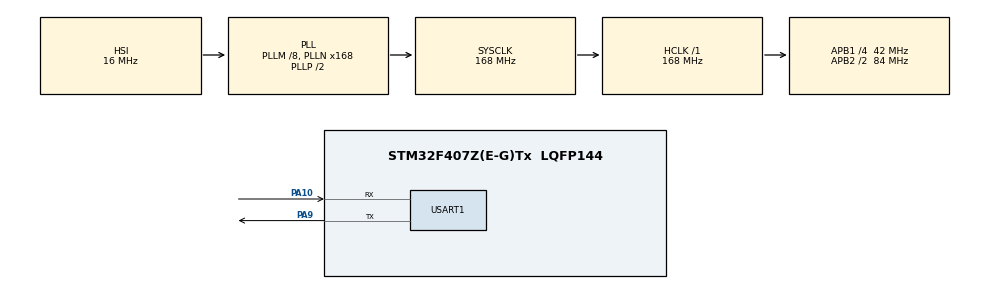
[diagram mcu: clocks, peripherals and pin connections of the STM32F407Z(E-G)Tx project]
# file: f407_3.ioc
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Mcu.Family=STM32F4
Mcu.Name=STM32F407Z(E-G)Tx
Mcu.Package=LQFP144
NVIC.PriorityGroup=NVIC_PRIORITYGROUP_4
PA10.Mode=Asynchronous
PA10.Signal=USART1_RX
PA9.Mode=Asynchronous
PA9.Signal=USART1_TX
ProjectManager.HeapSize=0x2000
ProjectManager.StackSize=0x4000
ProjectManager.TargetToolchain=MDK-ARM V5.32
RCC.48MHZClocksFreq_Value=84000000
RCC.AHBFreq_Value=168000000
RCC.APB1CLKDivider=RCC_HCLK_DIV4
RCC.APB1Freq_Value=42000000
RCC.APB1TimFreq_Value=84000000
RCC.APB2CLKDivider=RCC_HCLK_DIV2
RCC.APB2Freq_Value=84000000
RCC.APB2TimFreq_Value=168000000
RCC.CortexFreq_Value=168000000
RCC.HCLKFreq_Value=168000000
RCC.HSE_VALUE=25000000
RCC.HSI_VALUE=16000000
RCC.LSE_VALUE=32768
RCC.PLLM=8
RCC.PLLN=168
RCC.SYSCLKFreq_VALUE=168000000
RCC.SYSCLKSource=RCC_SYSCLKSOURCE_PLLCLK
RCC.VCOOutputFreq_Value=336000000
STMicroelectronics.X-CUBE-AI.9.1.0.ActivationBufferSizeList=1892
STMicroelectronics.X-CUBE-AI.9.1.0.ActivationBuffers=pool0
STMicroelectronics.X-CUBE-AI.9.1.0.ActivationNames=pool0
STMicroelectronics.X-CUBE-AI.9.1.0.ActivationSizes=AI_NETWORK_DATA_ACTIVATION_1_SIZE
STMicroelectronics.X-CUBE-AI.9.1.0.ApplicationCcDeviceJjApplication=ApplicationTemplate
STMicroelectronics.X-CUBE-AI.9.1.0.HeapSize=0x2000
STMicroelectronics.X-CUBE-AI.9.1.0.InternalRamActivationBufferMaxSize=AI_NETWORK_DATA_ACTIVATIONS_SIZE
STMicroelectronics.X-CUBE-AI.9.1.0.LatestDirectoryUsed-a4bf07f8dab8f3f992515cebb7d17788633882bc721fafc255fa8a93e3628871=D\:\\Repo\\Python_REPO\\Onnx_test
STMicroelectronics.X-CUBE-AI.9.1.0.MaximumNumberOfInputLayer=1
STMicroelectronics.X-CUBE-AI.9.1.0.MaximumNumberOfOutputLayer=1
STMicroelectronics.X-CUBE-AI.9.1.0.MaximumSizeOfInputLayer=1
STMicroelectronics.X-CUBE-AI.9.1.0.MaximumSizeOfOutputLayer=1
STMicroelectronics.X-CUBE-AI.9.1.0.ModelActualCompression-a4bf07f8dab8f3f992515cebb7d17788633882bc721fafc255fa8a93e3628871=0.0
STMicroelectronics.X-CUBE-AI.9.1.0.ModelCompression-a4bf07f8dab8f3f992515cebb7d17788633882bc721fafc255fa8a93e3628871=None
STMicroelectronics.X-CUBE-AI.9.1.0.ModelFlashOccupation-a4bf07f8dab8f3f992515cebb7d17788633882bc721fafc255fa8a93e3628871=564
STMicroelectronics.X-CUBE-AI.9.1.0.ModelHashList=a4bf07f8dab8f3f992515cebb7d17788633882bc721fafc255fa8a93e3628871
STMicroelectronics.X-CUBE-AI.9.1.0.ModelKind-a4bf07f8dab8f3f992515cebb7d17788633882bc721fafc255fa8a93e3628871=ONNX
STMicroelectronics.X-CUBE-AI.9.1.0.ModelMacc-a4bf07f8dab8f3f992515cebb7d17788633882bc721fafc255fa8a93e3628871=161
STMicroelectronics.X-CUBE-AI.9.1.0.ModelName-a4bf07f8dab8f3f992515cebb7d17788633882bc721fafc255fa8a93e3628871=network
STMicroelectronics.X-CUBE-AI.9.1.0.ModelNameList=network
STMicroelectronics.X-CUBE-AI.9.1.0.ModelRamOccupation-a4bf07f8dab8f3f992515cebb7d17788633882bc721fafc255fa8a93e3628871=80
STMicroelectronics.X-CUBE-AI.9.1.0.ModelStructureFile-a4bf07f8dab8f3f992515cebb7d17788633882bc721fafc255fa8a93e3628871=/D\:/Repo/Python_REPO/Onnx_test/complex_model.onnx
STMicroelectronics.X-CUBE-AI.9.1.0.ModelType-a4bf07f8dab8f3f992515cebb7d17788633882bc721fafc255fa8a93e3628871=STM32Cube.AI MCU runtime
STMicroelectronics.X-CUBE-AI.9.1.0.ReadyForCodeGeneration=true
STMicroelectronics.X-CUBE-AI.9.1.0.StackSize=0x4000
STMicroelectronics.X-CUBE-AI.9.1.0.WorkingBufferStartAddrList=0xFFFFFFFF
STMicroelectronics.X-CUBE-AI.9.1.0.XAaCUBEAaAICcArtificialOoIntelligenceJjCore=true
STMicroelectronics.X-CUBE-AI.9.1.0.copyWeightToRam=false
STMicroelectronics.X-CUBE-AI.9.1.0.customLayerConfigEnabled=false
STMicroelectronics.X-CUBE-AI.9.1.0.noOnnxIoTranspose=false
STMicroelectronics.X-CUBE-AI.9.1.0.useInputAllocation=true
STMicroelectronics.X-CUBE-AI.9.1.0.useOutputAllocation=true
USART1.VirtualMode=VM_ASYNC
VP_STMicroelectronics.X-CUBE-AI_VS_ArtificialOoIntelligenceJjXAaCUBEAaAI_9.1.0.Mode=ArtificialOoIntelligenceJjXAaCUBEAaAI
VP_STMicroelectronics.X-CUBE-AI_VS_DeviceJjApplication_9.1.0.Mode=DeviceJjApplication
board=custom

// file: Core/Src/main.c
/* USER CODE BEGIN Header */
/**
  ******************************************************************************
  * @file           : main.c
  * @brief          : Main program body
  ******************************************************************************
  * @attention
  *
  * Copyright (c) 2024 STMicroelectronics.
  * All rights reserved.
  *
  * This software is licensed under terms that can be found in the LICENSE file
  * in the root directory of this software component.
  * If no LICENSE file comes with this software, it is provided AS-IS.
  *
  ******************************************************************************
  */
/* USER CODE END Header */
#include "main.h"
#include "usart.h"
#include "gpio.h"
#include "app_x-cube-ai.h"
#include "stdio.h"

void SystemClock_Config(void);
/* USER CODE BEGIN PFP */
int _write(int file, char *data, int len)
{
    // 将数据通过 USART1 发送
    HAL_UART_Transmit(&huart1, (uint8_t*)data, len, HAL_MAX_DELAY);
    return len;
}
/* USER CODE END PFP */

int main(void)
{

  /* MCU Configuration--------------------------------------------------------*/

  /* Reset of all peripherals, Initializes the Flash interface and the Systick. */
  HAL_Init();

  /* Configure the system clock */
  SystemClock_Config();

  /* Initialize all configured peripherals */
  MX_GPIO_Init();
  MX_USART1_UART_Init();
  MX_X_CUBE_AI_Init();

  /* Infinite loop */
  while (1)
  {
    printf("输入0-5间的浮点数：\r\n");
    MX_X_CUBE_AI_Process();
  }
}

void SystemClock_Config(void)
{
  RCC_OscInitTypeDef RCC_OscInitStruct = {0};
  RCC_ClkInitTypeDef RCC_ClkInitStruct = {0};

  /** Configure the main internal regulator output voltage
  */
  __HAL_RCC_PWR_CLK_ENABLE();
  __HAL_PWR_VOLTAGESCALING_CONFIG(PWR_REGULATOR_VOLTAGE_SCALE1);

  /** Initializes the RCC Oscillators according to the specified parameters
  * in the RCC_OscInitTypeDef structure.
  */
  RCC_OscInitStruct.OscillatorType = RCC_OSCILLATORTYPE_HSI;
  RCC_OscInitStruct.HSIState = RCC_HSI_ON;
  RCC_OscInitStruct.HSICalibrationValue = RCC_HSICALIBRATION_DEFAULT;
  RCC_OscInitStruct.PLL.PLLState = RCC_PLL_ON;
  RCC_OscInitStruct.PLL.PLLSource = RCC_PLLSOURCE_HSI;
  RCC_OscInitStruct.PLL.PLLM = 8;
  RCC_OscInitStruct.PLL.PLLN = 168;
  RCC_OscInitStruct.PLL.PLLP = RCC_PLLP_DIV2;
  RCC_OscInitStruct.PLL.PLLQ = 4;
  if (HAL_RCC_OscConfig(&RCC_OscInitStruct) != HAL_OK)
  {
    Error_Handler();
  }

  /** Initializes the CPU, AHB and APB buses clocks
  */
  RCC_ClkInitStruct.ClockType = RCC_CLOCKTYPE_HCLK|RCC_CLOCKTYPE_SYSCLK
                              |RCC_CLOCKTYPE_PCLK1|RCC_CLOCKTYPE_PCLK2;
  RCC_ClkInitStruct.SYSCLKSource = RCC_SYSCLKSOURCE_PLLCLK;
  RCC_ClkInitStruct.AHBCLKDivider = RCC_SYSCLK_DIV1;
  RCC_ClkInitStruct.APB1CLKDivider = RCC_HCLK_DIV4;
  RCC_ClkInitStruct.APB2CLKDivider = RCC_HCLK_DIV2;

  if (HAL_RCC_ClockConfig(&RCC_ClkInitStruct, FLASH_LATENCY_5) != HAL_OK)
  {
    Error_Handler();
  }
}

void Error_Handler(void)
{
  __disable_irq();
  while (1)
  {
  }
}
